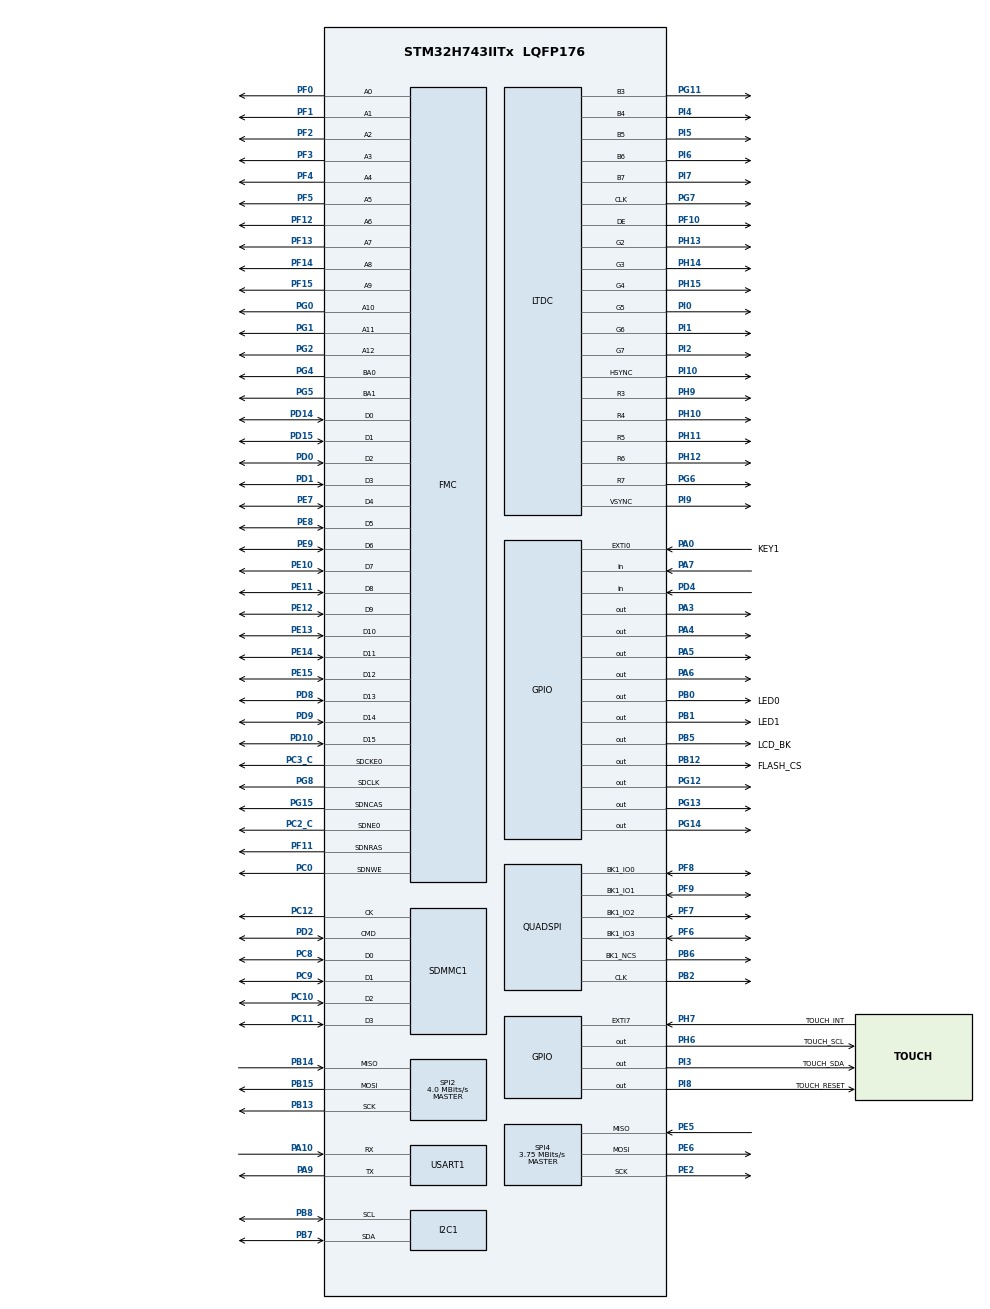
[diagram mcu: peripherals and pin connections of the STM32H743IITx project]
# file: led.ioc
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FMC.CASLatency1=FMC_SDRAM_CAS_LATENCY_3
FMC.ColumnBitsNumber1=FMC_SDRAM_COLUMN_BITS_NUM_9
FMC.ExitSelfRefreshDelay1=8
FMC.LoadToActiveDelay1=2
FMC.RCDDelay1=2
FMC.RPDelay1=2
FMC.ReadBurst1=FMC_SDRAM_RBURST_ENABLE
FMC.ReadPipeDelay1=FMC_SDRAM_RPIPE_DELAY_1
FMC.RowCycleDelay1=6
FMC.SDClockPeriod1=FMC_SDRAM_CLOCK_PERIOD_2
FMC.SelfRefreshTime1=6
FMC.WriteRecoveryTime1=4
I2C1.Timing=0x307075B1
LTDC.ActiveW=800
LTDC.Alpha_L0=255
LTDC.FBStartAdress_L0=0xc000000
LTDC.FBStartAdress_L1=0xc000000
LTDC.HBP=140
LTDC.HSync=20
LTDC.Layers=1
LTDC.PixelFormat_L0=LTDC_PIXEL_FORMAT_RGB565
LTDC.PixelFormat_L1=LTDC_PIXEL_FORMAT_RGB565
LTDC.VSync=3
LTDC.WindowX1_L0=800
LTDC.WindowY1_L0=480
Mcu.Family=STM32H7
Mcu.Name=STM32H743IITx
Mcu.Package=LQFP176
NVIC.EXTI0_IRQn=true\:0\:0\:false\:false\:true\:true\:true
NVIC.EXTI9_5_IRQn=true\:0\:0\:false\:false\:true\:true\:true
NVIC.PriorityGroup=NVIC_PRIORITYGROUP_4
NVIC.SDMMC1_IRQn=true\:0\:0\:false\:false\:true\:true\:true
NVIC.USART1_IRQn=true\:0\:0\:false\:false\:true\:true\:true
PA0.GPIO_Label=KEY1
PA0.GPIO_PuPd=GPIO_PULLDOWN
PA0.Signal=GPXTI0
PA10.Mode=Asynchronous
PA10.Signal=USART1_RX
PA13\ (JTMS/SWDIO).Mode=Trace_Asynchronous_SW
PA13\ (JTMS/SWDIO).Signal=DEBUG_JTMS-SWDIO
PA14\ (JTCK/SWCLK).Mode=Trace_Asynchronous_SW
PA14\ (JTCK/SWCLK).Signal=DEBUG_JTCK-SWCLK
PA3.Signal=GPIO_Output
PA4.Signal=GPIO_Output
PA5.Signal=GPIO_Output
PA6.Signal=GPIO_Output
PA7.GPIO_PuPd=GPIO_PULLDOWN
PA7.Signal=GPIO_Input
PA9.Mode=Asynchronous
PA9.Signal=USART1_TX
PB0.GPIO_Label=LED0
PB0.Signal=GPIO_Output
PB1.GPIO_Label=LED1
PB1.Signal=GPIO_Output
PB12.GPIO_Label=FLASH_CS
PB12.Signal=GPIO_Output
PB13.Mode=Full_Duplex_Master
PB13.Signal=SPI2_SCK
PB14.Mode=Full_Duplex_Master
PB14.Signal=SPI2_MISO
PB15.Mode=Full_Duplex_Master
PB15.Signal=SPI2_MOSI
PB2.Mode=Single Bank 1
PB2.Signal=QUADSPI_CLK
PB3\ (JTDO/TRACESWO).Mode=Trace_Asynchronous_SW
PB3\ (JTDO/TRACESWO).Signal=DEBUG_JTDO-SWO
PB5.GPIO_Label=LCD_BK
PB5.Signal=GPIO_Output
PB6.Mode=Single Bank 1
PB6.Signal=QUADSPI_BK1_NCS
PB7.GPIO_Pu=GPIO_PULLUP
PB7.Mode=I2C
PB7.Signal=I2C1_SDA
PB8.GPIO_Pu=GPIO_PULLUP
PB8.Mode=I2C
PB8.Signal=I2C1_SCL
PC0.Signal=FMC_SDNWE
PC10.Mode=SD_4_bits_Wide_bus
PC10.Signal=SDMMC1_D2
PC11.Mode=SD_4_bits_Wide_bus
PC11.Signal=SDMMC1_D3
PC12.Mode=SD_4_bits_Wide_bus
PC12.Signal=SDMMC1_CK
PC2_C.Mode=SdramChipSelect1_1
PC2_C.Signal=FMC_SDNE0
PC3_C.Mode=SdramChipSelect1_1
PC3_C.Signal=FMC_SDCKE0
PC8.Mode=SD_4_bits_Wide_bus
PC8.Signal=SDMMC1_D0
PC9.Mode=SD_4_bits_Wide_bus
PC9.Signal=SDMMC1_D1
PD0.Signal=FMC_D2_DA2
PD1.Signal=FMC_D3_DA3
PD10.Signal=FMC_D15_DA15
PD14.Signal=FMC_D0_DA0
PD15.Signal=FMC_D1_DA1
PD2.Mode=SD_4_bits_Wide_bus
PD2.Signal=SDMMC1_CMD
PD4.GPIO_PuPd=GPIO_PULLDOWN
PD4.Signal=GPIO_Input
PD8.Signal=FMC_D13_DA13
PD9.Signal=FMC_D14_DA14
PE0.Signal=FMC_NBL0
PE1.Signal=FMC_NBL1
PE10.Signal=FMC_D7_DA7
PE11.Signal=FMC_D8_DA8
PE12.Signal=FMC_D9_DA9
PE13.Signal=FMC_D10_DA10
PE14.Signal=FMC_D11_DA11
PE15.Signal=FMC_D12_DA12
PE2.Mode=Full_Duplex_Master
PE2.Signal=SPI4_SCK
PE5.Mode=Full_Duplex_Master
PE5.Signal=SPI4_MISO
PE6.Mode=Full_Duplex_Master
PE6.Signal=SPI4_MOSI
PE7.Signal=FMC_D4_DA4
PE8.Signal=FMC_D5_DA5
PE9.Signal=FMC_D6_DA6
PF0.Signal=FMC_A0
PF1.Signal=FMC_A1
PF10.GPIO_Speed=GPIO_SPEED_FREQ_VERY_HIGH
PF10.Mode=RGB565
PF10.Signal=LTDC_DE
PF11.Signal=FMC_SDNRAS
PF12.Signal=FMC_A6
PF13.Signal=FMC_A7
PF14.Signal=FMC_A8
PF15.Signal=FMC_A9
PF2.Signal=FMC_A2
PF3.Signal=FMC_A3
PF4.Signal=FMC_A4
PF5.Signal=FMC_A5
PF6.Mode=Single Bank 1
PF6.Signal=QUADSPI_BK1_IO3
PF7.Mode=Single Bank 1
PF7.Signal=QUADSPI_BK1_IO2
PF8.Mode=Single Bank 1
PF8.Signal=QUADSPI_BK1_IO0
PF9.Mode=Single Bank 1
PF9.Signal=QUADSPI_BK1_IO1
PG0.Signal=FMC_A10
PG1.Signal=FMC_A11
PG11.GPIO_Speed=GPIO_SPEED_FREQ_VERY_HIGH
PG11.Mode=RGB565
PG11.Signal=LTDC_B3
PG12.Signal=GPIO_Output
PG13.Signal=GPIO_Output
PG14.Signal=GPIO_Output
PG15.Signal=FMC_SDNCAS
PG2.Signal=FMC_A12
PG4.Signal=FMC_A14_BA0
PG5.Signal=FMC_A15_BA1
PG6.GPIO_Speed=GPIO_SPEED_FREQ_VERY_HIGH
PG6.Mode=RGB565
PG6.Signal=LTDC_R7
PG7.GPIO_Speed=GPIO_SPEED_FREQ_VERY_HIGH
PG7.Mode=RGB565
PG7.Signal=LTDC_CLK
PG8.Signal=FMC_SDCLK
PH0-OSC_IN\ (PH0).Mode=HSE-External-Oscillator
PH0-OSC_IN\ (PH0).Signal=RCC_OSC_IN
PH1-OSC_OUT\ (PH1).Mode=HSE-External-Oscillator
PH1-OSC_OUT\ (PH1).Signal=RCC_OSC_OUT
PH10.GPIO_Speed=GPIO_SPEED_FREQ_VERY_HIGH
PH10.Mode=RGB565
PH10.Signal=LTDC_R4
PH11.GPIO_Speed=GPIO_SPEED_FREQ_VERY_HIGH
PH11.Mode=RGB565
PH11.Signal=LTDC_R5
PH12.GPIO_Speed=GPIO_SPEED_FREQ_VERY_HIGH
PH12.Mode=RGB565
PH12.Signal=LTDC_R6
PH13.GPIO_Speed=GPIO_SPEED_FREQ_VERY_HIGH
PH13.Mode=RGB565
PH13.Signal=LTDC_G2
PH14.GPIO_Speed=GPIO_SPEED_FREQ_VERY_HIGH
PH14.Mode=RGB565
PH14.Signal=LTDC_G3
PH15.GPIO_Speed=GPIO_SPEED_FREQ_VERY_HIGH
PH15.Mode=RGB565
PH15.Signal=LTDC_G4
PH6.GPIO_Label=TOUCH_SCL
PH6.Signal=GPIO_Output
PH7.GPIO_Label=TOUCH_INT
PH7.GPIO_PuPd=GPIO_PULLUP
PH7.Signal=GPXTI7
PH9.GPIO_Speed=GPIO_SPEED_FREQ_VERY_HIGH
PH9.Mode=RGB565
PH9.Signal=LTDC_R3
PI0.GPIO_Speed=GPIO_SPEED_FREQ_VERY_HIGH
PI0.Mode=RGB565
PI0.Signal=LTDC_G5
PI1.GPIO_Speed=GPIO_SPEED_FREQ_VERY_HIGH
PI1.Mode=RGB565
PI1.Signal=LTDC_G6
PI10.GPIO_Speed=GPIO_SPEED_FREQ_VERY_HIGH
PI10.Mode=RGB565
PI10.Signal=LTDC_HSYNC
PI2.GPIO_Speed=GPIO_SPEED_FREQ_VERY_HIGH
PI2.Mode=RGB565
PI2.Signal=LTDC_G7
PI3.GPIO_Label=TOUCH_SDA
PI3.Signal=GPIO_Output
PI4.GPIO_Speed=GPIO_SPEED_FREQ_VERY_HIGH
PI4.Mode=RGB565
PI4.Signal=LTDC_B4
PI5.GPIO_Speed=GPIO_SPEED_FREQ_VERY_HIGH
PI5.Mode=RGB565
PI5.Signal=LTDC_B5
PI6.GPIO_Speed=GPIO_SPEED_FREQ_VERY_HIGH
PI6.Mode=RGB565
PI6.Signal=LTDC_B6
PI7.GPIO_Speed=GPIO_SPEED_FREQ_VERY_HIGH
PI7.Mode=RGB565
PI7.Signal=LTDC_B7
PI8.GPIO_Label=TOUCH_RESET
PI8.Signal=GPIO_Output
PI9.GPIO_Speed=GPIO_SPEED_FREQ_VERY_HIGH
PI9.Mode=RGB565
PI9.Signal=LTDC_VSYNC
ProjectManager.HeapSize=0x1000
ProjectManager.StackSize=0x1000
ProjectManager.TargetToolchain=MDK-ARM V5.27
QUADSPI.ChipSelectHighTime=QSPI_CS_HIGH_TIME_2_CYCLE
QUADSPI.ClockPrescaler=1
QUADSPI.FifoThreshold=4
QUADSPI.FlashSize=23
QUADSPI.SampleShifting=QSPI_SAMPLE_SHIFTING_HALFCYCLE
RCC.ADCFreq_Value=400000000
RCC.APB1Freq_Value=120000000
RCC.APB2Freq_Value=120000000
RCC.APB3Freq_Value=120000000
RCC.APB4Freq_Value=120000000
RCC.CortexFreq_Value=480000000
RCC.D1PPRE=RCC_APB3_DIV2
RCC.D2PPRE1=RCC_APB1_DIV2
RCC.D2PPRE2=RCC_APB2_DIV2
RCC.D3PPRE=RCC_APB4_DIV2
RCC.DIVM1=5
RCC.DIVM2=5
RCC.DIVM3=5
RCC.DIVN1=192
RCC.DIVN2=160
RCC.DIVN3=160
RCC.DIVR2=32
RCC.DIVR3=32
RCC.HCLKFreq_Value=240000000
RCC.HPRE=RCC_HCLK_DIV2
RCC.PLL2FRACN=0
RCC.PLL3FRACN=0
RCC.PLLFRACN=0
RCC.PLLSourceVirtual=RCC_PLLSOURCE_HSE
RCC.QSPICLockSelection=RCC_QSPICLKSOURCE_CLKP
RCC.SDMMC1CLockSelection=RCC_SDMMCCLKSOURCE_PLL2
RCC.SPI123CLockSelection=RCC_SPI123CLKSOURCE_CLKP
RCC.SYSCLKFreq_VALUE=480000000
RCC.SYSCLKSource=RCC_SYSCLKSOURCE_PLLCLK
RCC.USBFreq_Value=480000000
SDMMC1.ClockDiv=10
SH.FMC_A0.0=FMC_A0,13b-sda1
SH.FMC_A1.0=FMC_A1,13b-sda1
SH.FMC_A10.0=FMC_A10,13b-sda1
SH.FMC_A11.0=FMC_A11,13b-sda1
SH.FMC_A12.0=FMC_A12,13b-sda1
SH.FMC_A14_BA0.0=FMC_BA0,FourSdramBanks1
SH.FMC_A15_BA1.0=FMC_BA1,FourSdramBanks1
SH.FMC_A2.0=FMC_A2,13b-sda1
SH.FMC_A3.0=FMC_A3,13b-sda1
SH.FMC_A4.0=FMC_A4,13b-sda1
SH.FMC_A5.0=FMC_A5,13b-sda1
SH.FMC_A6.0=FMC_A6,13b-sda1
SH.FMC_A7.0=FMC_A7,13b-sda1
SH.FMC_A8.0=FMC_A8,13b-sda1
SH.FMC_A9.0=FMC_A9,13b-sda1
SH.FMC_D0_DA0.0=FMC_D0,sd-16b-d1
SH.FMC_D10_DA10.0=FMC_D10,sd-16b-d1
SH.FMC_D11_DA11.0=FMC_D11,sd-16b-d1
SH.FMC_D12_DA12.0=FMC_D12,sd-16b-d1
SH.FMC_D13_DA13.0=FMC_D13,sd-16b-d1
SH.FMC_D14_DA14.0=FMC_D14,sd-16b-d1
SH.FMC_D15_DA15.0=FMC_D15,sd-16b-d1
SH.FMC_D1_DA1.0=FMC_D1,sd-16b-d1
SH.FMC_D2_DA2.0=FMC_D2,sd-16b-d1
SH.FMC_D3_DA3.0=FMC_D3,sd-16b-d1
SH.FMC_D4_DA4.0=FMC_D4,sd-16b-d1
SH.FMC_D5_DA5.0=FMC_D5,sd-16b-d1
SH.FMC_D6_DA6.0=FMC_D6,sd-16b-d1
SH.FMC_D7_DA7.0=FMC_D7,sd-16b-d1
SH.FMC_D8_DA8.0=FMC_D8,sd-16b-d1
SH.FMC_D9_DA9.0=FMC_D9,sd-16b-d1
SH.FMC_NBL0.0=FMC_NBL0
SH.FMC_NBL1.0=FMC_NBL1
SH.FMC_SDCLK.0=FMC_SDCLK,13b-sda1
SH.FMC_SDNCAS.0=FMC_SDNCAS,13b-sda1
SH.FMC_SDNRAS.0=FMC_SDNRAS,13b-sda1
SH.FMC_SDNWE.0=FMC_SDNWE,13b-sda1
SPI2.BaudRatePrescaler=SPI_BAUDRATEPRESCALER_16
SPI2.CalculateBaudRate=4.0 MBits/s
SPI2.DataSize=SPI_DATASIZE_8BIT
SPI2.Direction=SPI_DIRECTION_2LINES
SPI2.Mode=SPI_MODE_MASTER
SPI2.VirtualType=VM_MASTER
SPI4.BaudRatePrescaler=SPI_BAUDRATEPRESCALER_32
SPI4.CalculateBaudRate=3.75 MBits/s
SPI4.DataSize=SPI_DATASIZE_8BIT
SPI4.Direction=SPI_DIRECTION_2LINES
SPI4.Mode=SPI_MODE_MASTER
SPI4.VirtualType=VM_MASTER
USART1.VirtualMode-Asynchronous=VM_ASYNC
VP_DMA2D_VS_DMA2D.Mode=DMA2D_Activate
board=custom

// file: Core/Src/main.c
/* USER CODE BEGIN Header */
/**
  ******************************************************************************
  * @file           : main.c
  * @brief          : Main program body
  ******************************************************************************
  * @attention
  *
  * <h2><center>&copy; Copyright (c) 2021 STMicroelectronics.
  * All rights reserved.</center></h2>
  *
  * This software component is licensed by ST under BSD 3-Clause license,
  * the "License"; You may not use this file except in compliance with the
  * License. You may obtain a copy of the License at:
  *                        opensource.org/licenses/BSD-3-Clause
  *
  ******************************************************************************
  */
/* USER CODE END Header */
#include "main.h"
#include "dma2d.h"
#include "i2c.h"
#include "ltdc.h"
#include "quadspi.h"
#include "sdmmc.h"
#include "usart.h"
#include "gpio.h"
#include "fmc.h"

/* USER CODE BEGIN Includes */

#include "zfos.h"
#include "base_app.h"
/* USER CODE END Includes */

void SystemClock_Config(void);
void PeriphCommonClock_Config(void);

int main(void)
{
  /* USER CODE BEGIN 1 */
    //Cache_Enable();
  /* USER CODE END 1 */

  /* MCU Configuration--------------------------------------------------------*/

  /* Reset of all peripherals, Initializes the Flash interface and the Systick. */
  HAL_Init();

  /* Configure the system clock */
  SystemClock_Config();

/* Configure the peripherals common clocks */
  PeriphCommonClock_Config();

  /* Initialize all configured peripherals */
  MX_GPIO_Init();
  MX_USART1_UART_Init();
  MX_SPI2_Init();
  MX_QUADSPI_Init();
  MX_SDMMC1_SD_Init();
  MX_FMC_Init();
  MX_DMA2D_Init();
  MX_LTDC_Init();
  MX_I2C1_Init();
  MX_SPI4_Init();
  /* USER CODE BEGIN 2 */
    MX_SDRAM_InitEx();

		char board_name[50]="stm32h743_io";
    struct zfos_t mzfos;
    mzfos.platform = ZFOS_PLATFORM_STM32;
    memcpy(mzfos.board_name,board_name,strlen(board_name)+1);
    mzfos.board_version = 1;

	  zfos_init(&mzfos);
  	app_init();

    // fsmc_sdram_test();
    //sdcard_fatfs_test();
  /* USER CODE END 2 */

  /* Infinite loop */
  /* USER CODE BEGIN WHILE */
    while (1)
    {

		HAL_Delay(500);

        //HAL_Delay(100);

    /* USER CODE END WHILE */

    }
}

void SystemClock_Config(void)
{
  RCC_OscInitTypeDef RCC_OscInitStruct = {0};
  RCC_ClkInitTypeDef RCC_ClkInitStruct = {0};

  /** Supply configuration update enable
  */
  HAL_PWREx_ConfigSupply(PWR_LDO_SUPPLY);
  /** Configure the main internal regulator output voltage
  */
  __HAL_PWR_VOLTAGESCALING_CONFIG(PWR_REGULATOR_VOLTAGE_SCALE0);

  while(!__HAL_PWR_GET_FLAG(PWR_FLAG_VOSRDY)) {}
  /** Macro to configure the PLL clock source
  */
  __HAL_RCC_PLL_PLLSOURCE_CONFIG(RCC_PLLSOURCE_HSE);
  /** Initializes the RCC Oscillators according to the specified parameters
  * in the RCC_OscInitTypeDef structure.
  */
  RCC_OscInitStruct.OscillatorType = RCC_OSCILLATORTYPE_HSI|RCC_OSCILLATORTYPE_HSE;
  RCC_OscInitStruct.HSEState = RCC_HSE_ON;
  RCC_OscInitStruct.HSIState = RCC_HSI_DIV1;
  RCC_OscInitStruct.HSICalibrationValue = RCC_HSICALIBRATION_DEFAULT;
  RCC_OscInitStruct.PLL.PLLState = RCC_PLL_ON;
  RCC_OscInitStruct.PLL.PLLSource = RCC_PLLSOURCE_HSE;
  RCC_OscInitStruct.PLL.PLLM = 5;
  RCC_OscInitStruct.PLL.PLLN = 192;
  RCC_OscInitStruct.PLL.PLLP = 2;
  RCC_OscInitStruct.PLL.PLLQ = 2;
  RCC_OscInitStruct.PLL.PLLR = 2;
  RCC_OscInitStruct.PLL.PLLRGE = RCC_PLL1VCIRANGE_2;
  RCC_OscInitStruct.PLL.PLLVCOSEL = RCC_PLL1VCOWIDE;
  RCC_OscInitStruct.PLL.PLLFRACN = 0;
  if (HAL_RCC_OscConfig(&RCC_OscInitStruct) != HAL_OK)
  {
    Error_Handler();
  }
  /** Initializes the CPU, AHB and APB buses clocks
  */
  RCC_ClkInitStruct.ClockType = RCC_CLOCKTYPE_HCLK|RCC_CLOCKTYPE_SYSCLK
                              |RCC_CLOCKTYPE_PCLK1|RCC_CLOCKTYPE_PCLK2
                              |RCC_CLOCKTYPE_D3PCLK1|RCC_CLOCKTYPE_D1PCLK1;
  RCC_ClkInitStruct.SYSCLKSource = RCC_SYSCLKSOURCE_PLLCLK;
  RCC_ClkInitStruct.SYSCLKDivider = RCC_SYSCLK_DIV1;
  RCC_ClkInitStruct.AHBCLKDivider = RCC_HCLK_DIV2;
  RCC_ClkInitStruct.APB3CLKDivider = RCC_APB3_DIV2;
  RCC_ClkInitStruct.APB1CLKDivider = RCC_APB1_DIV2;
  RCC_ClkInitStruct.APB2CLKDivider = RCC_APB2_DIV2;
  RCC_ClkInitStruct.APB4CLKDivider = RCC_APB4_DIV2;

  if (HAL_RCC_ClockConfig(&RCC_ClkInitStruct, FLASH_LATENCY_4) != HAL_OK)
  {
    Error_Handler();
  }
}

void PeriphCommonClock_Config(void)
{
  RCC_PeriphCLKInitTypeDef PeriphClkInitStruct = {0};

  /** Initializes the peripherals clock
  */
  PeriphClkInitStruct.PeriphClockSelection = RCC_PERIPHCLK_CKPER;
  PeriphClkInitStruct.CkperClockSelection = RCC_CLKPSOURCE_HSI;
  if (HAL_RCCEx_PeriphCLKConfig(&PeriphClkInitStruct) != HAL_OK)
  {
    Error_Handler();
  }
}

void Error_Handler(void)
{
}
